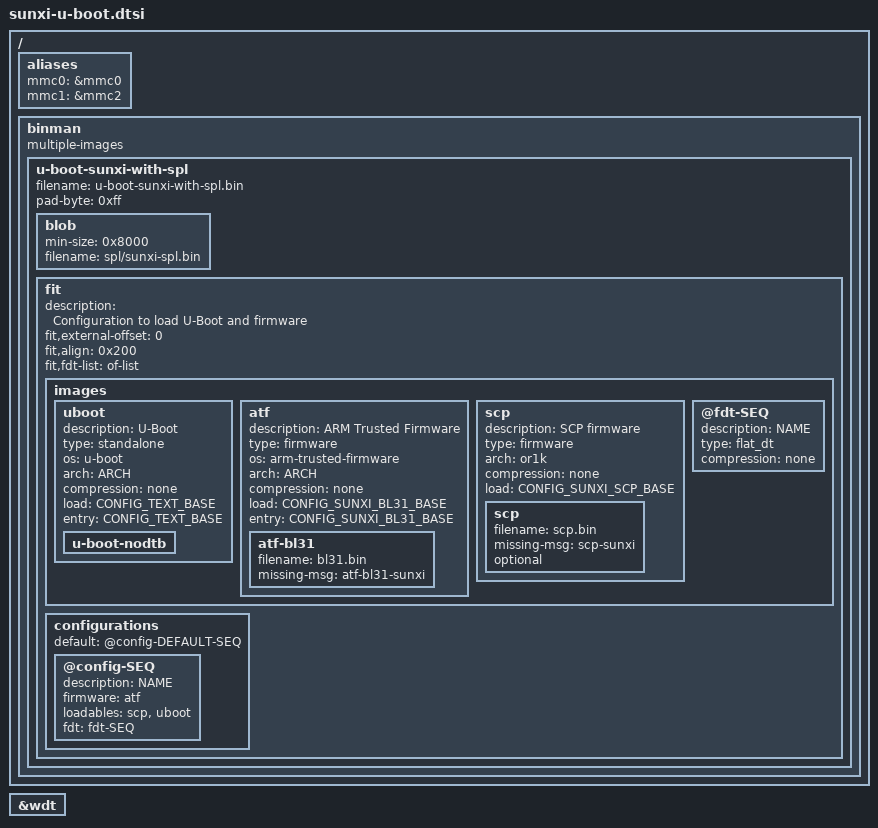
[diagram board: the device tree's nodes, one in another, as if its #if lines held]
#include <config.h>

#ifdef CONFIG_ARM64
#define ARCH "arm64"
#else
#define ARCH "arm"
#endif

/ {
	aliases {
		mmc0 = &mmc0;
#if CONFIG_MMC_SUNXI_SLOT_EXTRA == 2
		mmc1 = &mmc2;
#endif
	};

	binman: binman {
		multiple-images;
	};
};

/* Let U-Boot be the firmware layer that controls the watchdog. */
#ifdef CONFIG_MACH_SUN8I_R528
&wdt {
	status = "okay";
};
#endif

&binman {
	u-boot-sunxi-with-spl {
		filename = "u-boot-sunxi-with-spl.bin";
		pad-byte = <0xff>;

		blob {
			/*
			 * This value matches SYS_MMCSD_RAW_MODE_U_BOOT_SECTOR
			 * and SYS_SPI_U_BOOT_OFFS if those are defined.
			 */
			min-size = <0x8000>;
			filename = "spl/sunxi-spl.bin";
		};

#ifdef CONFIG_SPL_LOAD_FIT
		fit {
			description = "Configuration to load U-Boot and firmware";
			#address-cells = <1>;
			/*
			 * Keep the payloads outside the FIT structure, on block
			 * boundaries.  The SPL runs with the MMU off, so every
			 * load and store goes to Device-nGnRnE memory.  With the
			 * payloads embedded, spl_simple_fit_read() has to pull
			 * the whole FIT into a scratch buffer and load_simple_fit()
			 * then moves every image out of it again; lib/string.c
			 * memcpy() only copies words when source and destination
			 * share 8-byte alignment, which an embedded "data"
			 * property (4-byte aligned inside the FDT) does not, so
			 * the move degrades to one uncached byte at a time.  On
			 * the H713 that is 1.4 s for a 940 KiB FIT.
			 * With external data each image is read straight to its
			 * load address; the 512-byte alignment makes the
			 * source and destination of the trailing memmove()
			 * identical, so the move is skipped entirely.
			 */
			fit,external-offset = <0>;
			fit,align = <0x200>;
			fit,fdt-list = "of-list";

			images {
				uboot {
					description = "U-Boot";
					type = "standalone";
					os = "u-boot";
					arch = ARCH;
					compression = "none";
					load = <CONFIG_TEXT_BASE>;
#if CONFIG_SUNXI_BL31_BASE == 0
					entry = <CONFIG_TEXT_BASE>;
#endif

					u-boot-nodtb {
					};
				};

#if CONFIG_SUNXI_BL31_BASE
				atf {
					description = "ARM Trusted Firmware";
					type = "firmware";
					os = "arm-trusted-firmware";
					arch = ARCH;
					compression = "none";
					load = <CONFIG_SUNXI_BL31_BASE>;
					entry = <CONFIG_SUNXI_BL31_BASE>;

					atf-bl31 {
						filename = "bl31.bin";
						missing-msg = "atf-bl31-sunxi";
					};
				};
#endif

#if CONFIG_SUNXI_SCP_BASE
				scp {
					description = "SCP firmware";
					type = "firmware";
					arch = "or1k";
					compression = "none";
					load = <CONFIG_SUNXI_SCP_BASE>;

					scp {
						filename = "scp.bin";
						missing-msg = "scp-sunxi";
						optional;
					};
				};
#endif

				@fdt-SEQ {
					description = "NAME";
					type = "flat_dt";
					compression = "none";
				};
			};

			configurations {
				default = "@config-DEFAULT-SEQ";

				@config-SEQ {
					description = "NAME";
#if CONFIG_SUNXI_BL31_BASE
					firmware = "atf";
#else
					firmware = "uboot";
#endif
#if CONFIG_SUNXI_SCP_BASE
					loadables = "scp", "uboot";
#else
					loadables = "uboot";
#endif
					fdt = "fdt-SEQ";
				};
			};
		};
#else
		u-boot-img {
		};
#endif
	};
};
